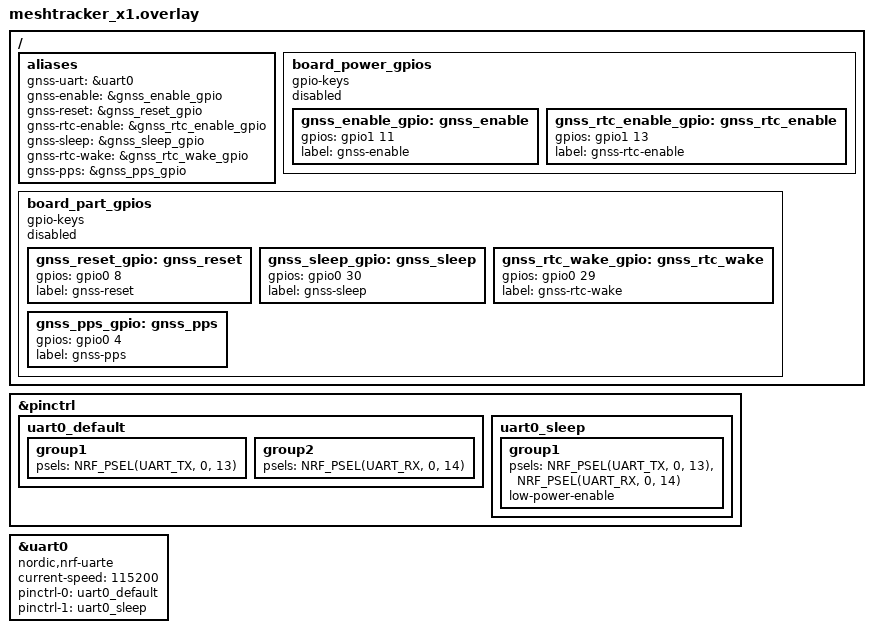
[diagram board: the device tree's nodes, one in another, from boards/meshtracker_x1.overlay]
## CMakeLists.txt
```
cmake_minimum_required(VERSION 3.20.0)

find_package(Zephyr REQUIRED HINTS $ENV{ZEPHYR_BASE})
project(ag3335_adapter LANGUAGES C CXX)

set(firmware ${CMAKE_CURRENT_SOURCE_DIR}/../../..)
target_include_directories(app PRIVATE ${firmware})
target_sources(app PRIVATE
  src/main.cpp
  ${firmware}/hardware/parts/ag3335/ag3335.cpp
  ${firmware}/hardware/parts/ag3335/pair.cpp
  ${firmware}/core/gnss/nmea.cpp
  ${firmware}/core/gnss/sky.cpp
  ${firmware}/core/gnss/validity.cpp
)
```

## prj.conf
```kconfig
CONFIG_CPP=y
CONFIG_STD_CPP20=y
CONFIG_CPP_EXCEPTIONS=n
CONFIG_CPP_RTTI=n
CONFIG_GLIBCXX_LIBCPP=y
CONFIG_REQUIRES_FULL_LIBC=y

CONFIG_GPIO=y
CONFIG_SERIAL=y
CONFIG_UART_INTERRUPT_DRIVEN=y

# The app opens the GNSS UART alone, so the board's USB console is left out.
CONFIG_CONSOLE=n
CONFIG_UART_CONSOLE=n
```

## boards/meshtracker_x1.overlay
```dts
/* INFO: fc 11nov26 #170's names for the AG3335 nodes, so on its board this overlay repeats them and adds nothing */
/* TODO: fc 11nov26 pins from SoftRF Seeed_X1.h:7-15 and Meshtastic variant.h:85-137, unverified until #169 */
/ {
	aliases {
		gnss-uart = &uart0;
		gnss-enable = &gnss_enable_gpio;
		gnss-reset = &gnss_reset_gpio;
		gnss-rtc-enable = &gnss_rtc_enable_gpio;
		gnss-sleep = &gnss_sleep_gpio;
		gnss-rtc-wake = &gnss_rtc_wake_gpio;
		gnss-pps = &gnss_pps_gpio;
	};

	board_power_gpios {
		compatible = "gpio-keys";
		status = "disabled";

		gnss_enable_gpio: gnss_enable {
			gpios = <&gpio1 11 GPIO_ACTIVE_HIGH>;
			label = "gnss-enable";
		};

		gnss_rtc_enable_gpio: gnss_rtc_enable {
			gpios = <&gpio1 13 GPIO_ACTIVE_HIGH>;
			label = "gnss-rtc-enable";
		};
	};

	board_part_gpios {
		compatible = "gpio-keys";
		status = "disabled";

		gnss_reset_gpio: gnss_reset {
			gpios = <&gpio0 8 GPIO_ACTIVE_HIGH>;
			label = "gnss-reset";
		};

		gnss_sleep_gpio: gnss_sleep {
			gpios = <&gpio0 30 GPIO_ACTIVE_HIGH>;
			label = "gnss-sleep";
		};

		gnss_rtc_wake_gpio: gnss_rtc_wake {
			gpios = <&gpio0 29 GPIO_ACTIVE_HIGH>;
			label = "gnss-rtc-wake";
		};

		gnss_pps_gpio: gnss_pps {
			gpios = <&gpio0 4 GPIO_ACTIVE_HIGH>;
			label = "gnss-pps";
		};
	};
};

&pinctrl {
	uart0_default: uart0_default {
		group1 {
			psels = <NRF_PSEL(UART_TX, 0, 13)>;
		};

		group2 {
			psels = <NRF_PSEL(UART_RX, 0, 14)>;
		};
	};

	uart0_sleep: uart0_sleep {
		group1 {
			psels = <NRF_PSEL(UART_TX, 0, 13)>, <NRF_PSEL(UART_RX, 0, 14)>;
			low-power-enable;
		};
	};
};

&uart0 {
	compatible = "nordic,nrf-uarte";
	status = "okay";
	current-speed = <115200>;
	pinctrl-0 = <&uart0_default>;
	pinctrl-1 = <&uart0_sleep>;
	pinctrl-names = "default", "sleep";
};
```

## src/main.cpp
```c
#include <zephyr/kernel.h>

#include "hardware/parts/ag3335/ag3335.h"
#include "hardware/platform/zephyr/ag3335.h"

using namespace skyblip;

namespace {

platform::zephyr::Ag3335Wiring g_wiring;

}  // namespace

int main(void) {
    if (g_wiring.begin() != Status::Ok) return -1;
    parts::Ag3335 gnss(g_wiring.uart());
    for (;;) {
        const uint32_t now_ms = k_uptime_get_32();
        gnss.service(now_ms);
        gnss.poll();
        k_msleep(10);
    }
    return 0;
}
```
